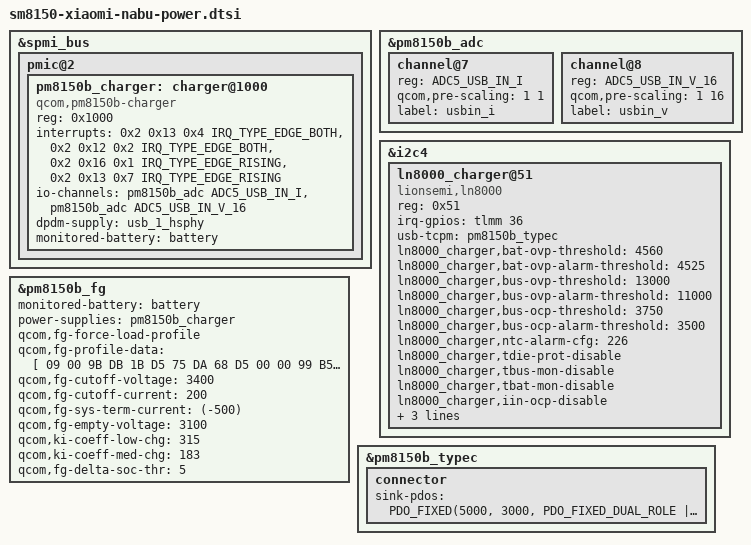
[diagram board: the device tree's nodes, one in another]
// SPDX-License-Identifier: BSD-3-Clause
/*
 * Battery and charger additions for Xiaomi Pad 5 (nabu).
 *
 * This file only appends the charging path to the kernel branch's own
 * sm8150-xiaomi-nabu.dts, which is used verbatim as the base device tree and
 * already provides the battery node.  The base DTS is never patched.
 */

#include <dt-bindings/interrupt-controller/irq.h>
#include <dt-bindings/iio/qcom,spmi-vadc.h>

/*
 * PM8150B SMB5 switch-mode charger. It provides the 5V USB charging path
 * (the LN8000 is a 2:1 charge pump that only works from 9V+ fast-charge
 * adapters). The Type-C/PD blocks stay owned by the pm8150b-typec driver.
 */
&spmi_bus {
	pmic@2 {
		pm8150b_charger: charger@1000 {
			compatible = "qcom,pm8150b-charger";
			reg = <0x1000>;

			interrupts = <0x2 0x13 0x4 IRQ_TYPE_EDGE_BOTH>,
				     <0x2 0x12 0x2 IRQ_TYPE_EDGE_BOTH>,
				     <0x2 0x16 0x1 IRQ_TYPE_EDGE_RISING>,
				     <0x2 0x13 0x7 IRQ_TYPE_EDGE_RISING>;
			interrupt-names = "usb-plugin",
					  "bat-ov",
					  "wdog-bark",
					  "usbin-icl-change";

			io-channels = <&pm8150b_adc ADC5_USB_IN_I>,
				      <&pm8150b_adc ADC5_USB_IN_V_16>;
			io-channel-names = "usbin_i", "usbin_v";

			/* Let the USB HS PHY release D+/D- for APSD/QC. */
			dpdm-supply = <&usb_1_hsphy>;

			monitored-battery = <&battery>;
			status = "okay";
		};
	};
};

&pm8150b_adc {
	channel@7 {
		reg = <ADC5_USB_IN_I>;
		qcom,pre-scaling = <1 1>;
		label = "usbin_i";
	};

	channel@8 {
		reg = <ADC5_USB_IN_V_16>;
		qcom,pre-scaling = <1 16>;
		label = "usbin_v";
	};
};

&i2c4 {
	ln8000_charger@51 {
		compatible = "lionsemi,ln8000";
		reg = <0x51>;

		status = "okay";

		irq-gpios = <&tlmm 36 0x2002>;

		usb-tcpm = <&pm8150b_typec>;

		ln8000_charger,bat-ovp-threshold = <4560>;
		ln8000_charger,bat-ovp-alarm-threshold = <4525>;
		ln8000_charger,bus-ovp-threshold = <13000>;
		ln8000_charger,bus-ovp-alarm-threshold = <11000>;
		ln8000_charger,bus-ocp-threshold = <3750>;
		ln8000_charger,bus-ocp-alarm-threshold = <3500>;
		ln8000_charger,ntc-alarm-cfg  = <226>;

		ln8000_charger,tdie-prot-disable;
		ln8000_charger,tbus-mon-disable;
		ln8000_charger,tbat-mon-disable;
		ln8000_charger,iin-ocp-disable;
		ln8000_charger,iin-reg-disable;
		ln8000_charger,tdie-reg-disable;
		ln8000_charger,vbat-reg-disable;
	};
};

&pm8150b_fg {
	status = "okay";
	monitored-battery = <&battery>;
	power-supplies = <&pm8150b_charger>;

	/*
	 * Battery model for the K82 sunwoda 8720mAh pack. The PM8150B gauge
	 * has no usable profile in OTP, so the driver pushes this 416-byte
	 * blob (taken verbatim from the vendor
	 * fg-gen4-batterydata-nabu-sunwoda-8720mah.dtsi) into gauge SRAM at
	 * boot and restarts the SOC algorithm. Without it the hardware SOC
	 * register reports a meaningless, near-full value.
	 */
	qcom,fg-force-load-profile;
	qcom,fg-profile-data = [
		09 00 9B DB 1B D5 75 DA 68 D5 00 00 99 B5 42 83
		FA 87 1E 93 02 8D EA 87 18 00 33 FC E8 12 C5 04
		50 02 CE 07 32 00 11 EA BB E4 48 E3 5E 0B B5 E2
		1D AC 12 22 C9 FA 3A CC 60 00 40 00 3F 00 38 00
		2C 00 2D 00 3A 00 46 00 41 00 46 00 3E 00 60 00
		44 00 3B 00 4B 00 47 00 3D 00 8C 00 59 64 4B 00
		49 00 4C 08 60 00 4C 00 4F 00 6F 10 5E 10 57 00
		A3 28 6B 48 5B 60 54 0C 58 00 D8 08 06 20 B1 14
		6F 0B 51 FD 4B 1C AE 03 5B 05 F7 2A B6 17 51 42
		2A 5D 68 02 66 12 54 23 AD 0C DE 12 9D 0D F3 1C
		21 FB 58 FD 50 03 FE 16 09 2A 76 44 18 5A 95 11
		9E 24 29 DC 21 C3 72 C5 F3 1C 97 AA FB 04 2D B2
		0A 17 12 82 4A 84 43 8A A4 90 09 80 48 03 13 05
		87 02 D7 05 00 00 FB CD 78 E2 FC 07 17 EA 39 CD
		1D 18 15 08 80 ED 35 03 76 05 A7 01 CE 07 32 00
		9E 01 EE 05 5C 05 1C 03 D4 05 0E 02 BD 03 9D 02
		C6 05 48 00 39 00 42 00 44 64 45 00 49 00 40 08
		40 00 44 00 44 00 3B 10 3F 10 3F 00 53 28 54 48
		57 58 62 0D 43 00 48 00 52 08 54 00 43 00 47 00
		49 10 59 10 51 00 5F 20 75 40 49 58 56 0F 5D 00
		4C 08 31 10 D8 08 FC 20 54 FC 6D 03 67 0D C7 1C
		62 23 C5 45 4B 52 63 18 0F 02 AC 05 A9 03 72 12
		3F 0A 6B 20 93 04 89 03 20 05 BE 1C 3C 03 C0 05
		85 02 77 18 A0 03 51 04 9A 02 6A 00 35 22 4D 05
		7A 02 EB 05 FB 1C AF 03 82 04 0B 02 86 18 17 03
		59 05 23 03 8A 00 92 00 C0 00 FA 00 F0 21 00 00
	];

	/* SOC algorithm configuration, matching the vendor FG node. */
	qcom,fg-cutoff-voltage = <3400>;
	qcom,fg-cutoff-current = <200>;
	qcom,fg-sys-term-current = <(-500)>;
	qcom,fg-empty-voltage = <3100>;
	qcom,ki-coeff-low-chg = <315>;
	qcom,ki-coeff-med-chg = <183>;
	qcom,fg-delta-soc-thr = <5>;
};

&pm8150b_typec {
	connector {
		sink-pdos = <PDO_FIXED(5000, 3000,
					 PDO_FIXED_DUAL_ROLE |
					 PDO_FIXED_USB_COMM |
					 PDO_FIXED_DATA_SWAP)
					 PDO_VAR(5000, 9000, 3000)>;
	};
};
